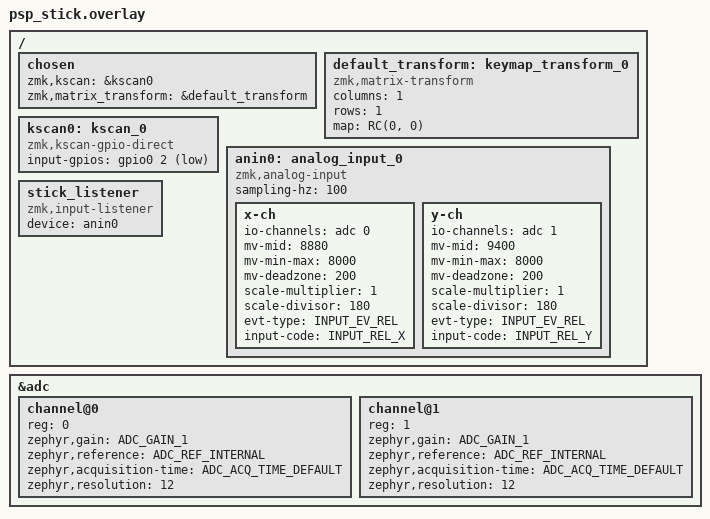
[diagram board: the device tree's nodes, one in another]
/*
 * PSP 2-axis analog stick as a USB mouse pointer on RP2040.
 *
 * Wiring (3.3V ONLY — do not feed the pot with 5V into the ADC):
 *   Module VCC -> board 3V3
 *   Module GND -> GND
 *   Module VRx -> GPIO26 (ADC0)  — Pro Micro label A0 / D18 / Pico GP26
 *   Module VRy -> GPIO27 (ADC1)  — Pro Micro label A1 / D19 / Pico GP27
 */

#include <dt-bindings/zmk/matrix_transform.h>
#include <zephyr/dt-bindings/input/input-event-codes.h>
#include <zephyr/dt-bindings/adc/adc.h>

&adc {
	status = "okay";
	#address-cells = <1>;
	#size-cells = <0>;

	channel@0 {
		reg = <0>;
		zephyr,gain = "ADC_GAIN_1";
		zephyr,reference = "ADC_REF_INTERNAL";
		zephyr,acquisition-time = <ADC_ACQ_TIME_DEFAULT>;
		zephyr,resolution = <12>;
	};

	channel@1 {
		reg = <1>;
		zephyr,gain = "ADC_GAIN_1";
		zephyr,reference = "ADC_REF_INTERNAL";
		zephyr,acquisition-time = <ADC_ACQ_TIME_DEFAULT>;
		zephyr,resolution = <12>;
	};
};

/ {
	chosen {
		zmk,kscan = &kscan0;
		zmk,matrix_transform = &default_transform;
	};

	default_transform: keymap_transform_0 {
		compatible = "zmk,matrix-transform";
		columns = <1>;
		rows = <1>;
		map = <RC(0, 0)>;
	};

	/* Optional click pad on GPIO2 (pull-up; unused if no switch) */
	kscan0: kscan_0 {
		compatible = "zmk,kscan-gpio-direct";
		input-gpios = <&gpio0 2 (GPIO_ACTIVE_LOW | GPIO_PULL_UP)>;
	};

	/*
	 * Driver converts with ADC_GAIN_1_6 (reported mV ≈ real×6).
	 * Measured at rest on this stick (COM13): X≈8880 mV, Y≈9400 mV.
	 */
	anin0: analog_input_0 {
		compatible = "zmk,analog-input";
		sampling-hz = <100>;

		x-ch {
			io-channels = <&adc 0>; /* GPIO26 */
			mv-mid = <8880>;
			mv-min-max = <8000>;
			mv-deadzone = <200>;
			scale-multiplier = <1>;
			scale-divisor = <180>;
			evt-type = <INPUT_EV_REL>;
			input-code = <INPUT_REL_X>;
		};

		y-ch {
			io-channels = <&adc 1>; /* GPIO27 */
			mv-mid = <9400>;
			mv-min-max = <8000>;
			mv-deadzone = <200>;
			scale-multiplier = <1>;
			scale-divisor = <180>;
			evt-type = <INPUT_EV_REL>;
			input-code = <INPUT_REL_Y>;
		};
	};

	stick_listener {
		compatible = "zmk,input-listener";
		device = <&anin0>;
	};
};
